# j7am_pulsar0_mem_cbass0_GLB register map
Vendor: Texas Instruments
Peripheral module from a debugger description file (folder J7_AHP).
Registers are 32-bit, read-only, reset 0x0 unless marked. A register's access mark holds for its fields unless they carry their own. Offsets are as the file gives them; lines under a group give offsets from that group; [hi:lo] are bit positions; {n}, {i} and the like mark numbered series; 'fields as' and 'values as' point back to an identical list; <NAME> marks a mode.

## j7am_pulsar0_mem_cbass0_GLB
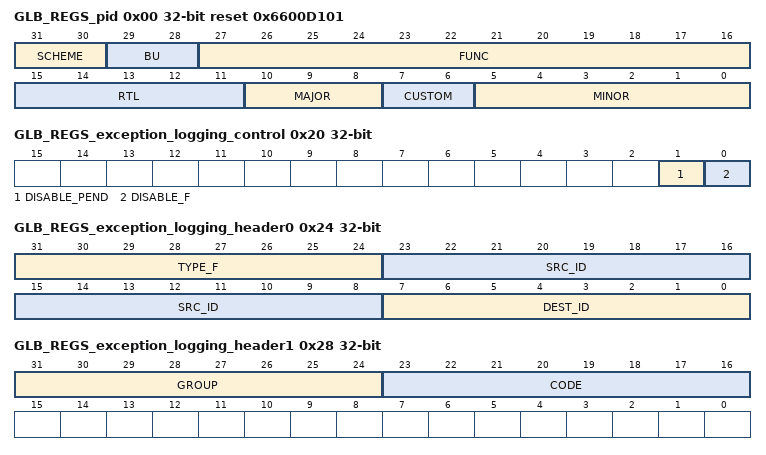
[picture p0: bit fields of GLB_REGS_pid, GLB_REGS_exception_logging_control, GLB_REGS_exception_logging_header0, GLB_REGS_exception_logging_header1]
0x00 GLB_REGS_pid reset 0x6600D101
  [31:30] SCHEME — PID register scheme
  [29:28] BU — Business Unit: 10 = Processors
  [27:16] FUNC — Module ID
  [15:11] RTL — RTL revision. Will vary depending on release.
  [10:8] MAJOR — Major revision
  [7:6] CUSTOM
  [5:0] MINOR — Minor revision
0x04 GLB_REGS_destination_id rw
  [7:0] DEST_ID — The destination ID.
0x20 GLB_REGS_exception_logging_control rw
  [1] DISABLE_PEND — Disables logging pending when set.
  [0] DISABLE_F — Disables logging when set.
0x24 GLB_REGS_exception_logging_header0
  [31:24] TYPE_F — Type.
  [23:8] SRC_ID — Source ID.
  [7:0] DEST_ID — Destination ID.
0x28 GLB_REGS_exception_logging_header1
  [31:24] GROUP, [23:16] CODE
0x2C GLB_REGS_exception_logging_data0
  [31:0] ADDR_L — Address lower 32 bits.
0x30 GLB_REGS_exception_logging_data1
  [15:0] ADDR_H — Address upper 16 bits.
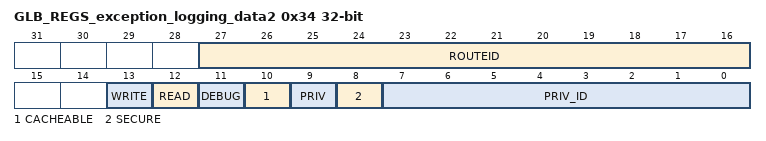
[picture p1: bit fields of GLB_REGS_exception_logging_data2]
0x34 GLB_REGS_exception_logging_data2
  [27:16] ROUTEID, [13] WRITE, [12] READ, [11] DEBUG, [10] CACHEABLE, [9] PRIV, [8] SECURE, [7:0] PRIV_ID
0x38 GLB_REGS_exception_logging_data3
  [9:0] BYTECNT — Byte count.
0x40 GLB_REGS_exception_pend_set access not given
  [0] PEND_SET — Write a 1 to set the exception pend signal. (access R/W1TS)
0x44 GLB_REGS_exception_pend_clear access not given
  [0] PEND_CLR — Write a 1 to clear the exception pend signal. (access R/W1TC)
